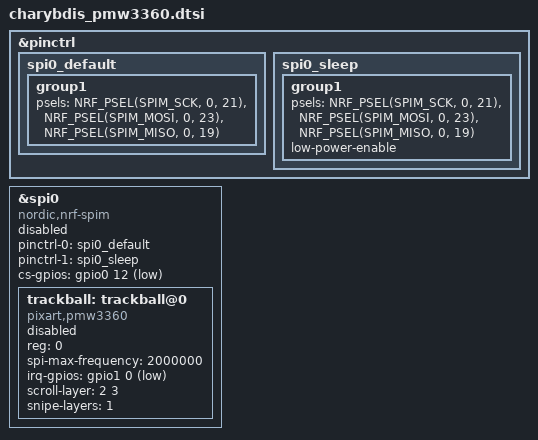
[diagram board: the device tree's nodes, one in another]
&pinctrl {
    spi0_default: spi0_default {
        group1 {
            psels = <NRF_PSEL(SPIM_SCK, 0, 21)>,
                    <NRF_PSEL(SPIM_MOSI, 0, 23)>,
                    <NRF_PSEL(SPIM_MISO, 0, 19)>;
        };
    };

    spi0_sleep: spi0_sleep {
        group1 {
            psels = <NRF_PSEL(SPIM_SCK, 0, 21)>,
                    <NRF_PSEL(SPIM_MOSI, 0, 23)>,
                    <NRF_PSEL(SPIM_MISO, 0, 19)>;
                    low-power-enable;
        };
    };
};

&spi0 {
    status = "disabled";
    compatible = "nordic,nrf-spim";
    pinctrl-0 = <&spi0_default>;
    pinctrl-1 = <&spi0_sleep>;
    pinctrl-names = "default", "sleep";
    cs-gpios = <&gpio0 12 GPIO_ACTIVE_LOW>;

  trackball: trackball@0 {
    status = "disabled";
    compatible = "pixart,pmw3360";
    reg = <0>;
    spi-max-frequency = <2000000>;
    irq-gpios = <&gpio1 0 (GPIO_ACTIVE_LOW | GPIO_PULL_UP)>;
    //automouse-layer = <4>;
    scroll-layer = <2 3>;
    snipe-layers = <1>;
  };
};
